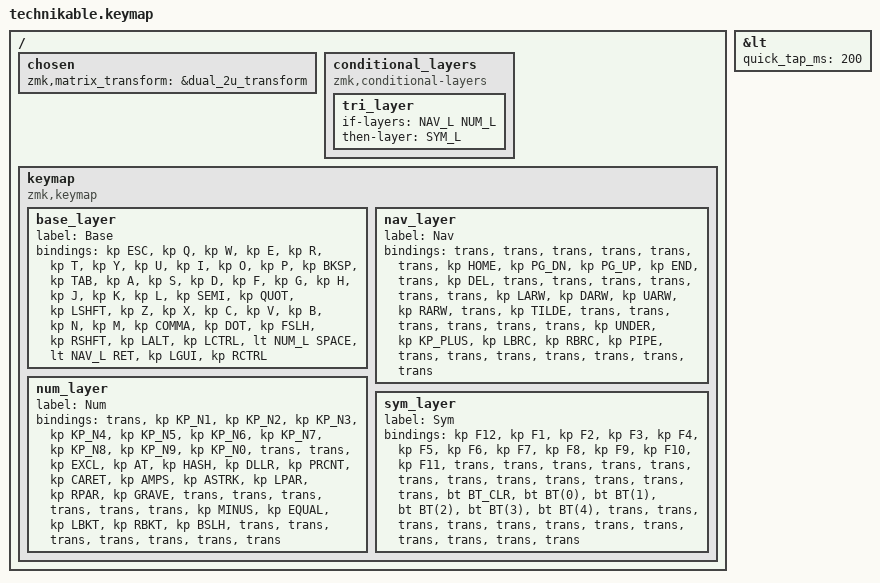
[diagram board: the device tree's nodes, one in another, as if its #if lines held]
/*
 * Copyright (c) 2022 Pete Johanson
 *
 * SPDX-License-Identifier: MIT
 */

#include <behaviors.dtsi>
#include <dt-bindings/zmk/keys.h>
#include <dt-bindings/zmk/bt.h>
#include <dt-bindings/zmk/outputs.h>

#define QWERTY_BASE 1

#define TBLE_ORTHO   true
// #define TBLE_MIT     true
// #define TBLE_DUAL_2U true

#define BAS_L 0
#define NAV_L 1
#define NUM_L 2
#define SYM_L 3

// Using layer taps on thumbs, having quick tap as well helps w/ repeating space/backspace
&lt { quick_tap_ms = <200>; };

#define BT(n) BT_SEL n

/ {
    chosen {
       zmk,matrix_transform =
#ifdef TBLE_DUAL_2U
                       &dual_2u_transform;
#elif defined(TBLE_MIT)
                       &mit_transform;
#else
                       &ortho_transform;
#endif
    };

    conditional_layers {
        compatible = "zmk,conditional-layers";
	tri_layer {
	    if-layers = <NAV_L NUM_L>;
	    then-layer = <SYM_L>;
	};
    };

    keymap {
        compatible = "zmk,keymap";

        base_layer {
            label = "Base";
            bindings = <
#ifdef QWERTY_BASE
 &kp ESC    &kp Q      &kp W      &kp E       &kp R          &kp T          &kp Y            &kp U          &kp I       &kp O      &kp P         &kp BKSP
 &kp TAB    &kp A      &kp S      &kp D       &kp F          &kp G          &kp H            &kp J          &kp K       &kp L      &kp SEMI      &kp QUOT
 &kp LSHFT  &kp Z      &kp X      &kp C       &kp V          &kp B          &kp N            &kp M          &kp COMMA   &kp DOT    &kp FSLH      &kp RSHFT
#else
 &kp ESC    &kp Q      &kp W      &kp F       &kp P          &kp B          &kp J            &kp L          &kp U       &kp Y      &kp QUOT     &kp BKSP
 &kp TAB    &kp A      &kp R      &kp S       &kp T          &kp G          &kp M            &kp N          &kp E       &kp I      &kp O        &kp QUOT
 &kp LSHFT  &kp Z      &kp X      &kp C       &kp D          &kp V          &kp K            &kp H          &kp COMMA   &kp DOT    &kp FSLH     &kp RSHFT
#endif
#ifdef TBLE_DUAL_2U
                       &kp LALT   &kp LCTRL         &lt NUM_L SPACE                &lt NAV_L RET            &kp LGUI   &kp RCTRL
#elif defined(TBLE_MIT)
                       &kp LALT   &kp LCTRL   &mo NUM_L              &kp SPACE               &mo NAV_L      &kp LGUI    &kp RCTRL
#else
                       &kp LALT   &kp LCTRL   &mo NUM_L      &kp SPACE      &kp RET          &mo NAV_L      &kp LGUI    &kp RCTRL
#endif
            >;
        };

        nav_layer {
            label = "Nav";
            bindings = <
&trans     &trans     &trans     &trans      &trans          &trans       &kp HOME    &kp PG_DN    &kp PG_UP  &kp END    &trans     &kp DEL
&trans     &trans     &trans     &trans      &trans          &trans       &kp LARW    &kp DARW     &kp UARW   &kp RARW   &trans     &kp TILDE
&trans     &trans     &trans     &trans      &trans          &trans       &kp UNDER   &kp KP_PLUS  &kp LBRC   &kp RBRC   &kp PIPE   &trans
#ifdef TBLE_DUAL_2U
                      &trans     &trans              &trans                    &trans       &trans            &trans
#elif defined(TBLE_MIT)
                      &trans     &trans      &trans                &trans             &trans       &trans     &trans
#else
                      &trans     &trans      &trans          &trans       &trans      &trans       &trans     &trans
#endif
            >;
        };

        num_layer {
            label = "Num";
            bindings = <
&trans     &kp KP_N1  &kp KP_N2  &kp KP_N3   &kp KP_N4    &kp KP_N5   &kp KP_N6    &kp KP_N7   &kp KP_N8  &kp KP_N9    &kp KP_N0  &trans
&trans     &kp EXCL   &kp AT     &kp HASH    &kp DLLR     &kp PRCNT   &kp CARET    &kp AMPS    &kp ASTRK  &kp LPAR     &kp RPAR   &kp GRAVE
&trans     &trans     &trans     &trans      &trans       &trans      &kp MINUS    &kp EQUAL   &kp LBKT   &kp RBKT     &kp BSLH   &trans
#ifdef TBLE_DUAL_2U
                      &trans     &trans             &trans                 &trans              &trans     &trans
#elif defined(TBLE_MIT)
                      &trans     &trans      &trans            &trans              &trans      &trans     &trans
#else
                      &trans     &trans      &trans       &trans      &trans       &trans      &trans     &trans
#endif
            >;
        };

        sym_layer {
            label = "Sym";
            bindings = <
&kp F12    &kp F1     &kp F2     &kp F3      &kp F4     &kp F5     &kp F6     &kp F7    &kp F8       &kp F9       &kp F10    &kp F11
&trans     &trans     &trans     &trans      &trans     &trans     &trans     &trans    &trans       &trans       &trans     &trans
&bt BT_CLR &bt BT(0)  &bt BT(1)  &bt BT(2)   &bt BT(3)  &bt BT(4)  &trans     &trans    &trans       &trans       &trans     &trans
#ifdef TBLE_DUAL_2U
                      &trans     &trans              &trans             &trans          &trans       &trans
#elif defined(TBLE_MIT)
                      &trans     &trans      &trans           &trans          &trans    &trans       &trans
#else
                      &trans     &trans      &trans     &trans     &trans     &trans    &trans       &trans
#endif
            >;
        };

    };
};

